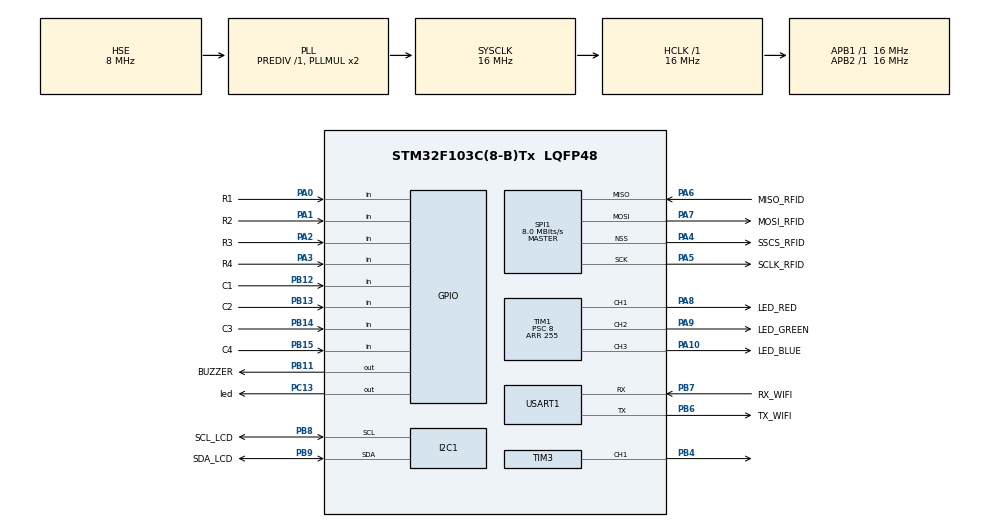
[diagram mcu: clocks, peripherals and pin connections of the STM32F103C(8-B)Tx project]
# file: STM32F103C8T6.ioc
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Mcu.Family=STM32F1
Mcu.Name=STM32F103C(8-B)Tx
Mcu.Package=LQFP48
NVIC.PriorityGroup=NVIC_PRIORITYGROUP_4
NVIC.TIM2_IRQn=true\:0\:0\:false\:false\:true\:true\:true
NVIC.USART1_IRQn=true\:0\:0\:false\:false\:true\:true\:true
PA0-WKUP.GPIO_Label=R1
PA0-WKUP.GPIO_PuPd=GPIO_PULLUP
PA0-WKUP.Signal=GPIO_Input
PA1.GPIO_Label=R2
PA1.Signal=GPIO_Input
PA10.GPIO_Label=LED_BLUE
PA10.Signal=S_TIM1_CH3
PA13.Mode=Serial_Wire
PA13.Signal=SYS_JTMS-SWDIO
PA14.Mode=Serial_Wire
PA14.Signal=SYS_JTCK-SWCLK
PA2.GPIO_Label=R3
PA2.GPIO_PuPd=GPIO_PULLUP
PA2.Signal=GPIO_Input
PA3.GPIO_Label=R4
PA3.GPIO_PuPd=GPIO_PULLUP
PA3.Signal=GPIO_Input
PA4.GPIO_Label=SSCS_RFID
PA4.Mode=NSS_Signal_Hard_Output
PA4.Signal=SPI1_NSS
PA5.GPIO_Label=SCLK_RFID
PA5.Mode=Full_Duplex_Master
PA5.Signal=SPI1_SCK
PA6.GPIO_Label=MISO_RFID
PA6.Mode=Full_Duplex_Master
PA6.Signal=SPI1_MISO
PA7.GPIO_Label=MOSI_RFID
PA7.Mode=Full_Duplex_Master
PA7.Signal=SPI1_MOSI
PA8.GPIO_Label=LED_RED
PA8.Signal=S_TIM1_CH1
PA9.GPIO_Label=LED_GREEN
PA9.Signal=S_TIM1_CH2
PB11.GPIO_Label=BUZZER
PB11.Signal=GPIO_Output
PB12.GPIO_Label=C1
PB12.Signal=GPIO_Input
PB13.GPIO_Label=C2
PB13.Signal=GPIO_Input
PB14.GPIO_Label=C3
PB14.Signal=GPIO_Input
PB15.GPIO_Label=C4
PB15.Signal=GPIO_Input
PB4.Signal=S_TIM3_CH1
PB6.GPIO_Label=TX_WIFI
PB6.Mode=Asynchronous
PB6.Signal=USART1_TX
PB7.GPIO_Label=RX_WIFI
PB7.Mode=Asynchronous
PB7.Signal=USART1_RX
PB8.GPIO_Label=SCL_LCD
PB8.Mode=I2C
PB8.Signal=I2C1_SCL
PB9.GPIO_Label=SDA_LCD
PB9.Mode=I2C
PB9.Signal=I2C1_SDA
PC13-TAMPER-RTC.GPIO_Label=led
PC13-TAMPER-RTC.Signal=GPIO_Output
PD0-OSC_IN.Mode=HSE-External-Oscillator
PD0-OSC_IN.Signal=RCC_OSC_IN
PD1-OSC_OUT.Mode=HSE-External-Oscillator
PD1-OSC_OUT.Signal=RCC_OSC_OUT
ProjectManager.HeapSize=0x200
ProjectManager.StackSize=0x400
ProjectManager.TargetToolchain=STM32CubeIDE
RCC.AHBFreq_Value=16000000
RCC.APB1Freq_Value=16000000
RCC.APB1TimFreq_Value=16000000
RCC.APB2Freq_Value=16000000
RCC.APB2TimFreq_Value=16000000
RCC.HCLKFreq_Value=16000000
RCC.PLLSourceVirtual=RCC_PLLSOURCE_HSE
RCC.SYSCLKFreq_VALUE=16000000
RCC.SYSCLKSource=RCC_SYSCLKSOURCE_PLLCLK
RCC.USBFreq_Value=16000000
SH.S_TIM1_CH1.0=TIM1_CH1,PWM Generation1 CH1
SH.S_TIM1_CH2.0=TIM1_CH2,PWM Generation2 CH2
SH.S_TIM1_CH3.0=TIM1_CH3,PWM Generation3 CH3
SH.S_TIM3_CH1.0=TIM3_CH1,PWM Generation1 CH1
SPI1.CalculateBaudRate=8.0 MBits/s
SPI1.Direction=SPI_DIRECTION_2LINES
SPI1.Mode=SPI_MODE_MASTER
SPI1.VirtualNSS=VM_NSSHARD
SPI1.VirtualType=VM_MASTER
TIM1.AutoReloadPreload=TIM_AUTORELOAD_PRELOAD_ENABLE
TIM1.Channel-PWM\ Generation1\ CH1=TIM_CHANNEL_1
TIM1.Channel-PWM\ Generation2\ CH2=TIM_CHANNEL_2
TIM1.Channel-PWM\ Generation3\ CH3=TIM_CHANNEL_3
TIM1.Period=255
TIM1.Prescaler=8
TIM1.Pulse-PWM\ Generation1\ CH1=50
TIM1.Pulse-PWM\ Generation2\ CH2=50
TIM1.Pulse-PWM\ Generation3\ CH3=50
TIM2.Prescaler=7999
TIM3.Channel-PWM\ Generation1\ CH1=TIM_CHANNEL_1
TIM3.Period=1000
TIM3.Pulse-PWM\ Generation1\ CH1=500
USART1.VirtualMode=VM_ASYNC
VP_TIM1_VS_ClockSourceINT.Mode=Internal
VP_TIM2_VS_ClockSourceINT.Mode=Internal
VP_TIM3_VS_ClockSourceINT.Mode=Internal
board=custom

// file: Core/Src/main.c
/* USER CODE BEGIN Header */
/**
  ******************************************************************************
  * @file           : main.c
  * @brief          : Main program body
  ******************************************************************************
  * @attention
  *
  * <h2><center>&copy; Copyright (c) 2024 STMicroelectronics.
  * All rights reserved.</center></h2>
  *
  * This software component is licensed by ST under BSD 3-Clause license,
  * the "License"; You may not use this file except in compliance with the
  * License. You may obtain a copy of the License at:
  *                        opensource.org/licenses/BSD-3-Clause
  *
  ******************************************************************************
  */
/* USER CODE END Header */
#include "main.h"

/* USER CODE BEGIN Includes */
#include "signal.h"
/* USER CODE END Includes */

I2C_HandleTypeDef hi2c1;

SPI_HandleTypeDef hspi1;

TIM_HandleTypeDef htim1;
TIM_HandleTypeDef htim2;
TIM_HandleTypeDef htim3;

UART_HandleTypeDef huart1;

void SystemClock_Config(void);
static void MX_TIM2_Init(void);
static void MX_GPIO_Init(void);
static void MX_I2C1_Init(void);
static void MX_SPI1_Init(void);
static void MX_TIM1_Init(void);
static void MX_USART1_UART_Init(void);
static void MX_TIM3_Init(void);

int main(void)
{

  /* MCU Configuration--------------------------------------------------------*/

  /* Reset of all peripherals, Initializes the Flash interface and the Systick. */
  HAL_Init();

  /* Configure the system clock */
  SystemClock_Config();

  /* Initialize all configured peripherals */
  MX_TIM2_Init();
  MX_GPIO_Init();
  MX_I2C1_Init();
  MX_SPI1_Init();
  MX_TIM1_Init();
  MX_USART1_UART_Init();
  MX_TIM3_Init();
  /* USER CODE BEGIN 2 */
  lcd_init();

  //LED RGB INIT
  ledRgb_init();

  /* USER CODE END 2 */

  /* Infinite loop */
  /* USER CODE BEGIN WHILE */
  while (1)
  {
	  correct();
	  HAL_Delay(1000);
	  wrong();
	  HAL_Delay(1000);
	  reset();
	  HAL_Delay(3000);
    /* USER CODE END WHILE */

  }
}

void SystemClock_Config(void)
{
  RCC_OscInitTypeDef RCC_OscInitStruct = {0};
  RCC_ClkInitTypeDef RCC_ClkInitStruct = {0};

  /** Initializes the RCC Oscillators according to the specified parameters
  * in the RCC_OscInitTypeDef structure.
  */
  RCC_OscInitStruct.OscillatorType = RCC_OSCILLATORTYPE_HSE;
  RCC_OscInitStruct.HSEState = RCC_HSE_ON;
  RCC_OscInitStruct.HSEPredivValue = RCC_HSE_PREDIV_DIV1;
  RCC_OscInitStruct.HSIState = RCC_HSI_ON;
  RCC_OscInitStruct.PLL.PLLState = RCC_PLL_ON;
  RCC_OscInitStruct.PLL.PLLSource = RCC_PLLSOURCE_HSE;
  RCC_OscInitStruct.PLL.PLLMUL = RCC_PLL_MUL2;
  if (HAL_RCC_OscConfig(&RCC_OscInitStruct) != HAL_OK)
  {
    Error_Handler();
  }
  /** Initializes the CPU, AHB and APB buses clocks
  */
  RCC_ClkInitStruct.ClockType = RCC_CLOCKTYPE_HCLK|RCC_CLOCKTYPE_SYSCLK
                              |RCC_CLOCKTYPE_PCLK1|RCC_CLOCKTYPE_PCLK2;
  RCC_ClkInitStruct.SYSCLKSource = RCC_SYSCLKSOURCE_PLLCLK;
  RCC_ClkInitStruct.AHBCLKDivider = RCC_SYSCLK_DIV1;
  RCC_ClkInitStruct.APB1CLKDivider = RCC_HCLK_DIV1;
  RCC_ClkInitStruct.APB2CLKDivider = RCC_HCLK_DIV1;

  if (HAL_RCC_ClockConfig(&RCC_ClkInitStruct, FLASH_LATENCY_0) != HAL_OK)
  {
    Error_Handler();
  }
}

static void MX_I2C1_Init(void)
{

  hi2c1.Instance = I2C1;
  hi2c1.Init.ClockSpeed = 100000;
  hi2c1.Init.DutyCycle = I2C_DUTYCYCLE_2;
  hi2c1.Init.OwnAddress1 = 0;
  hi2c1.Init.AddressingMode = I2C_ADDRESSINGMODE_7BIT;
  hi2c1.Init.DualAddressMode = I2C_DUALADDRESS_DISABLE;
  hi2c1.Init.OwnAddress2 = 0;
  hi2c1.Init.GeneralCallMode = I2C_GENERALCALL_DISABLE;
  hi2c1.Init.NoStretchMode = I2C_NOSTRETCH_DISABLE;
  if (HAL_I2C_Init(&hi2c1) != HAL_OK)
  {
    Error_Handler();
  }

}

static void MX_SPI1_Init(void)
{

  /* SPI1 parameter configuration*/
  hspi1.Instance = SPI1;
  hspi1.Init.Mode = SPI_MODE_MASTER;
  hspi1.Init.Direction = SPI_DIRECTION_2LINES;
  hspi1.Init.DataSize = SPI_DATASIZE_8BIT;
  hspi1.Init.CLKPolarity = SPI_POLARITY_LOW;
  hspi1.Init.CLKPhase = SPI_PHASE_1EDGE;
  hspi1.Init.NSS = SPI_NSS_HARD_OUTPUT;
  hspi1.Init.BaudRatePrescaler = SPI_BAUDRATEPRESCALER_2;
  hspi1.Init.FirstBit = SPI_FIRSTBIT_MSB;
  hspi1.Init.TIMode = SPI_TIMODE_DISABLE;
  hspi1.Init.CRCCalculation = SPI_CRCCALCULATION_DISABLE;
  hspi1.Init.CRCPolynomial = 10;
  if (HAL_SPI_Init(&hspi1) != HAL_OK)
  {
    Error_Handler();
  }

}

static void MX_TIM1_Init(void)
{

  TIM_ClockConfigTypeDef sClockSourceConfig = {0};
  TIM_MasterConfigTypeDef sMasterConfig = {0};
  TIM_OC_InitTypeDef sConfigOC = {0};
  TIM_BreakDeadTimeConfigTypeDef sBreakDeadTimeConfig = {0};

  htim1.Instance = TIM1;
  htim1.Init.Prescaler = 8;
  htim1.Init.CounterMode = TIM_COUNTERMODE_UP;
  htim1.Init.Period = 255;
  htim1.Init.ClockDivision = TIM_CLOCKDIVISION_DIV1;
  htim1.Init.RepetitionCounter = 0;
  htim1.Init.AutoReloadPreload = TIM_AUTORELOAD_PRELOAD_ENABLE;
  if (HAL_TIM_Base_Init(&htim1) != HAL_OK)
  {
    Error_Handler();
  }
  sClockSourceConfig.ClockSource = TIM_CLOCKSOURCE_INTERNAL;
  if (HAL_TIM_ConfigClockSource(&htim1, &sClockSourceConfig) != HAL_OK)
  {
    Error_Handler();
  }
  if (HAL_TIM_PWM_Init(&htim1) != HAL_OK)
  {
    Error_Handler();
  }
  sMasterConfig.MasterOutputTrigger = TIM_TRGO_RESET;
  sMasterConfig.MasterSlaveMode = TIM_MASTERSLAVEMODE_DISABLE;
  if (HAL_TIMEx_MasterConfigSynchronization(&htim1, &sMasterConfig) != HAL_OK)
  {
    Error_Handler();
  }
  sConfigOC.OCMode = TIM_OCMODE_PWM1;
  sConfigOC.Pulse = 50;
  sConfigOC.OCPolarity = TIM_OCPOLARITY_HIGH;
  sConfigOC.OCNPolarity = TIM_OCNPOLARITY_HIGH;
  sConfigOC.OCFastMode = TIM_OCFAST_DISABLE;
  sConfigOC.OCIdleState = TIM_OCIDLESTATE_RESET;
  sConfigOC.OCNIdleState = TIM_OCNIDLESTATE_RESET;
  if (HAL_TIM_PWM_ConfigChannel(&htim1, &sConfigOC, TIM_CHANNEL_1) != HAL_OK)
  {
    Error_Handler();
  }
  if (HAL_TIM_PWM_ConfigChannel(&htim1, &sConfigOC, TIM_CHANNEL_2) != HAL_OK)
  {
    Error_Handler();
  }
  if (HAL_TIM_PWM_ConfigChannel(&htim1, &sConfigOC, TIM_CHANNEL_3) != HAL_OK)
  {
    Error_Handler();
  }
  sBreakDeadTimeConfig.OffStateRunMode = TIM_OSSR_DISABLE;
  sBreakDeadTimeConfig.OffStateIDLEMode = TIM_OSSI_DISABLE;
  sBreakDeadTimeConfig.LockLevel = TIM_LOCKLEVEL_OFF;
  sBreakDeadTimeConfig.DeadTime = 0;
  sBreakDeadTimeConfig.BreakState = TIM_BREAK_DISABLE;
  sBreakDeadTimeConfig.BreakPolarity = TIM_BREAKPOLARITY_HIGH;
  sBreakDeadTimeConfig.AutomaticOutput = TIM_AUTOMATICOUTPUT_DISABLE;
  if (HAL_TIMEx_ConfigBreakDeadTime(&htim1, &sBreakDeadTimeConfig) != HAL_OK)
  {
    Error_Handler();
  }
  HAL_TIM_MspPostInit(&htim1);

}

static void MX_TIM2_Init(void)
{

  TIM_ClockConfigTypeDef sClockSourceConfig = {0};
  TIM_MasterConfigTypeDef sMasterConfig = {0};

  htim2.Instance = TIM2;
  htim2.Init.Prescaler = 7999;
  htim2.Init.CounterMode = TIM_COUNTERMODE_UP;
  htim2.Init.Period = 65535;
  htim2.Init.ClockDivision = TIM_CLOCKDIVISION_DIV1;
  htim2.Init.AutoReloadPreload = TIM_AUTORELOAD_PRELOAD_DISABLE;
  if (HAL_TIM_Base_Init(&htim2) != HAL_OK)
  {
    Error_Handler();
  }
  sClockSourceConfig.ClockSource = TIM_CLOCKSOURCE_INTERNAL;
  if (HAL_TIM_ConfigClockSource(&htim2, &sClockSourceConfig) != HAL_OK)
  {
    Error_Handler();
  }
  sMasterConfig.MasterOutputTrigger = TIM_TRGO_RESET;
  sMasterConfig.MasterSlaveMode = TIM_MASTERSLAVEMODE_DISABLE;
  if (HAL_TIMEx_MasterConfigSynchronization(&htim2, &sMasterConfig) != HAL_OK)
  {
    Error_Handler();
  }

}

static void MX_TIM3_Init(void)
{

  TIM_ClockConfigTypeDef sClockSourceConfig = {0};
  TIM_MasterConfigTypeDef sMasterConfig = {0};
  TIM_OC_InitTypeDef sConfigOC = {0};

  htim3.Instance = TIM3;
  htim3.Init.Prescaler = 0;
  htim3.Init.CounterMode = TIM_COUNTERMODE_UP;
  htim3.Init.Period = 1000;
  htim3.Init.ClockDivision = TIM_CLOCKDIVISION_DIV1;
  htim3.Init.AutoReloadPreload = TIM_AUTORELOAD_PRELOAD_DISABLE;
  if (HAL_TIM_Base_Init(&htim3) != HAL_OK)
  {
    Error_Handler();
  }
  sClockSourceConfig.ClockSource = TIM_CLOCKSOURCE_INTERNAL;
  if (HAL_TIM_ConfigClockSource(&htim3, &sClockSourceConfig) != HAL_OK)
  {
    Error_Handler();
  }
  if (HAL_TIM_PWM_Init(&htim3) != HAL_OK)
  {
    Error_Handler();
  }
  sMasterConfig.MasterOutputTrigger = TIM_TRGO_RESET;
  sMasterConfig.MasterSlaveMode = TIM_MASTERSLAVEMODE_DISABLE;
  if (HAL_TIMEx_MasterConfigSynchronization(&htim3, &sMasterConfig) != HAL_OK)
  {
    Error_Handler();
  }
  sConfigOC.OCMode = TIM_OCMODE_PWM1;
  sConfigOC.Pulse = 500;
  sConfigOC.OCPolarity = TIM_OCPOLARITY_HIGH;
  sConfigOC.OCFastMode = TIM_OCFAST_DISABLE;
  if (HAL_TIM_PWM_ConfigChannel(&htim3, &sConfigOC, TIM_CHANNEL_1) != HAL_OK)
  {
    Error_Handler();
  }
  HAL_TIM_MspPostInit(&htim3);

}

static void MX_USART1_UART_Init(void)
{

  huart1.Instance = USART1;
  huart1.Init.BaudRate = 115200;
  huart1.Init.WordLength = UART_WORDLENGTH_8B;
  huart1.Init.StopBits = UART_STOPBITS_1;
  huart1.Init.Parity = UART_PARITY_NONE;
  huart1.Init.Mode = UART_MODE_TX_RX;
  huart1.Init.HwFlowCtl = UART_HWCONTROL_NONE;
  huart1.Init.OverSampling = UART_OVERSAMPLING_16;
  if (HAL_UART_Init(&huart1) != HAL_OK)
  {
    Error_Handler();
  }

}

static void MX_GPIO_Init(void)
{
  GPIO_InitTypeDef GPIO_InitStruct = {0};

  /* GPIO Ports Clock Enable */
  __HAL_RCC_GPIOC_CLK_ENABLE();
  __HAL_RCC_GPIOD_CLK_ENABLE();
  __HAL_RCC_GPIOA_CLK_ENABLE();
  __HAL_RCC_GPIOB_CLK_ENABLE();

  /*Configure GPIO pin Output Level */
  HAL_GPIO_WritePin(led_GPIO_Port, led_Pin, GPIO_PIN_RESET);

  /*Configure GPIO pin Output Level */
  HAL_GPIO_WritePin(BUZZER_GPIO_Port, BUZZER_Pin, GPIO_PIN_RESET);

  /*Configure GPIO pin : led_Pin */
  GPIO_InitStruct.Pin = led_Pin;
  GPIO_InitStruct.Mode = GPIO_MODE_OUTPUT_PP;
  GPIO_InitStruct.Pull = GPIO_NOPULL;
  GPIO_InitStruct.Speed = GPIO_SPEED_FREQ_LOW;
  HAL_GPIO_Init(led_GPIO_Port, &GPIO_InitStruct);

  /*Configure GPIO pins : R1_Pin R3_Pin R4_Pin */
  GPIO_InitStruct.Pin = R1_Pin|R3_Pin|R4_Pin;
  GPIO_InitStruct.Mode = GPIO_MODE_INPUT;
  GPIO_InitStruct.Pull = GPIO_PULLUP;
  HAL_GPIO_Init(GPIOA, &GPIO_InitStruct);

  /*Configure GPIO pin : R2_Pin */
  GPIO_InitStruct.Pin = R2_Pin;
  GPIO_InitStruct.Mode = GPIO_MODE_INPUT;
  GPIO_InitStruct.Pull = GPIO_NOPULL;
  HAL_GPIO_Init(R2_GPIO_Port, &GPIO_InitStruct);

  /*Configure GPIO pin : BUZZER_Pin */
  GPIO_InitStruct.Pin = BUZZER_Pin;
  GPIO_InitStruct.Mode = GPIO_MODE_OUTPUT_PP;
  GPIO_InitStruct.Pull = GPIO_NOPULL;
  GPIO_InitStruct.Speed = GPIO_SPEED_FREQ_LOW;
  HAL_GPIO_Init(BUZZER_GPIO_Port, &GPIO_InitStruct);

  /*Configure GPIO pins : C1_Pin C2_Pin C3_Pin C4_Pin */
  GPIO_InitStruct.Pin = C1_Pin|C2_Pin|C3_Pin|C4_Pin;
  GPIO_InitStruct.Mode = GPIO_MODE_INPUT;
  GPIO_InitStruct.Pull = GPIO_NOPULL;
  HAL_GPIO_Init(GPIOB, &GPIO_InitStruct);

}

void Error_Handler(void)
{
  __disable_irq();
  while (1)
  {
  }
}

/************************ (C) COPYRIGHT STMicroelectronics *****END OF FILE****/
